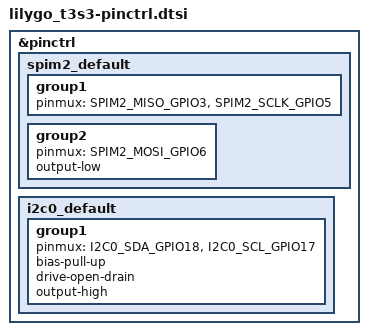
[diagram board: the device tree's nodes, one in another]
/*
 * SPDX-License-Identifier: MIT
 * LilyGo T3S3 — Pin Control Definitions
 *
 * Pin mapping (from Arduino MeshCore variants/lilygo_t3s3):
 *   SPI2 LoRa: SCLK=GPIO5, MOSI=GPIO6, MISO=GPIO3, NSS=GPIO7 (GPIO CS)
 *   LoRa ctrl: RESET=GPIO8, BUSY=GPIO34, DIO1=GPIO33 (DIO2 = RF switch)
 *   I2C0:      SDA=GPIO18, SCL=GPIO17   (SSD1306 OLED @0x3C, RST=GPIO21)
 *   Button:    GPIO0
 *   TX LED:    GPIO37
 *   VBAT ADC:  GPIO1
 *   Console:   USB Serial/JTAG (native)
 */

#include <zephyr/dt-bindings/pinctrl/esp-pinctrl-common.h>
#include <zephyr/dt-bindings/pinctrl/esp32s3-pinctrl.h>
#include <zephyr/dt-bindings/pinctrl/esp32s3-gpio-sigmap.h>

&pinctrl {
	/* SPI2 — SX1262 LoRa (CS via cs-gpios, not pinctrl) */
	spim2_default: spim2_default {
		group1 {
			pinmux = <SPIM2_MISO_GPIO3>,
				 <SPIM2_SCLK_GPIO5>;
		};
		group2 {
			pinmux = <SPIM2_MOSI_GPIO6>;
			output-low;
		};
	};

	/* I2C0 — SSD1306 OLED + optional sensors */
	i2c0_default: i2c0_default {
		group1 {
			pinmux = <I2C0_SDA_GPIO18>,
				 <I2C0_SCL_GPIO17>;
			bias-pull-up;
			drive-open-drain;
			output-high;
		};
	};
};
